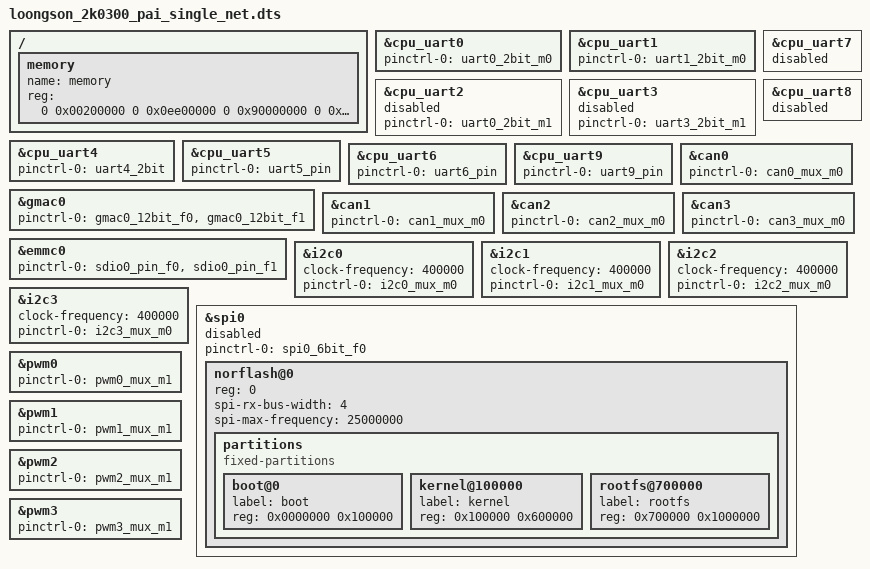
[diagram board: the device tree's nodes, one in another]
#include "loongson_2k0300.dtsi"

/ {
	memory {
         name = "memory";
         device_type = "memory";
         reg =  <0 0x00200000 0 0x0ee00000
             0 0x90000000 0 0x30000000>;
	};
};

&cpu_uart0{
    status = "okay";
    pinctrl-names = "default";
    pinctrl-0 = <&uart0_2bit_m0>;
};

&cpu_uart1{
    status = "okay";
    pinctrl-names = "default";
    pinctrl-0 = <&uart1_2bit_m0>;
};

&cpu_uart2{
    status = "disabled";
    pinctrl-names = "default";
    pinctrl-0 = <&uart0_2bit_m1>;
};

&cpu_uart3{
    status = "disabled";
    pinctrl-names = "default";
    pinctrl-0 = <&uart3_2bit_m1>;
};
&cpu_uart4{
    status = "okay";
    pinctrl-names = "default";
    pinctrl-0 = <&uart4_2bit>;
};

&cpu_uart5{
    status = "okay";
    pinctrl-names = "default";
    pinctrl-0 = <&uart5_pin>;
};

&cpu_uart6{
    status = "okay";
    pinctrl-names = "default";
    pinctrl-0 = <&uart6_pin>;
};

&cpu_uart7{
    status = "disabled";
};

&cpu_uart8{
    status = "disabled";
};

&cpu_uart9{
    status = "okay";
    pinctrl-names = "default";
    pinctrl-0 = <&uart9_pin>;
};

&gmac0{
    status = "okay";
    pinctrl-names = "default";
    pinctrl-0 = <&gmac0_12bit_f0>, <&gmac0_12bit_f1>;
};

&can0{
    status = "okay";
    pinctrl-names = "default";
    pinctrl-0 = <&can0_mux_m0>;
};
&can1{
    status = "okay";
    pinctrl-names = "default";
    pinctrl-0 = <&can1_mux_m0>;
};
&can2{
    status = "okay";
    pinctrl-names = "default";
    pinctrl-0 = <&can2_mux_m0>;
};
&can3{
    status = "okay";
    pinctrl-names = "default";
    pinctrl-0 = <&can3_mux_m0>;
};

&emmc0{
    status = "okay";
    pinctrl-names = "default";
    pinctrl-0 = <&sdio0_pin_f0>, <&sdio0_pin_f1>;
};
#if 0
&sdio1{
    status = "okay"; 
    pinctrl-names = "default"; 
    pinctrl-0 = <&sdio1_6bit>, <&sdio1_10bit_m1>;
};
#endif
&i2c0{
	status = "okay"; 
    clock-frequency = <400000>;
    pinctrl-names = "default"; 
    pinctrl-0 = <&i2c0_mux_m0>;
};
&i2c1{
	status = "okay"; 
    clock-frequency = <400000>;
    pinctrl-names = "default"; 
    pinctrl-0 = <&i2c1_mux_m0>;
};
&i2c2{
	status = "okay"; 
    clock-frequency = <400000>;
    pinctrl-names = "default"; 
    pinctrl-0 = <&i2c2_mux_m0>;
};
&i2c3{
	status = "okay"; 
    clock-frequency = <400000>;
    pinctrl-names = "default"; 
    pinctrl-0 = <&i2c3_mux_m0>;
};

&spi0{
	status = "disable"; 
    pinctrl-names = "default"; 
    pinctrl-0 = <&spi0_6bit_f0>;

	norflash@0 {
       reg = <0>;
       spi-rx-bus-width = <4>;
       spi-max-frequency = <25000000>;
       #address-cells = <1>;
       #size-cells = <1>;
       partitions {
               compatible = "fixed-partitions";
           #address-cells = <1>;
           #size-cells = <1>;

           boot@0 {
               label = "boot";
               reg = <0x0000000 0x100000>;
               /*read-only;*/
           };

           kernel@100000 {
               label = "kernel";
               reg = <0x100000 0x600000>;
           };

           rootfs@700000 {
               label = "rootfs";
               reg = <0x700000 0x1000000>;
           };
       };

    };

};
#if 0
&spi3{
	status = "okay"; 
    pinctrl-names = "default"; 
    pinctrl-0 = <&spi3_pin>;
};
#endif
&pwm0{
	status = "okay"; 
    pinctrl-names = "default"; 
    pinctrl-0 = <&pwm0_mux_m1>;
};

&pwm1{
	status = "okay"; 
    pinctrl-names = "default"; 
    pinctrl-0 = <&pwm1_mux_m1>;
};

&pwm2{
	status = "okay"; 
    pinctrl-names = "default"; 
    pinctrl-0 = <&pwm2_mux_m1>;
};

&pwm3{
	status = "okay"; 
    pinctrl-names = "default"; 
    pinctrl-0 = <&pwm3_mux_m1>;
};



